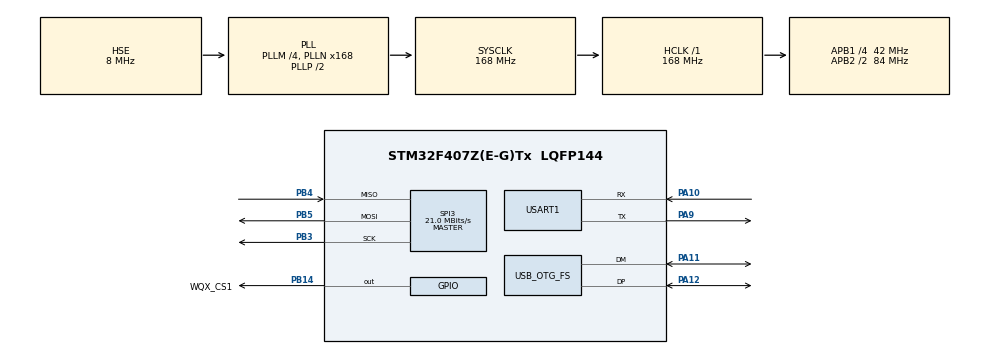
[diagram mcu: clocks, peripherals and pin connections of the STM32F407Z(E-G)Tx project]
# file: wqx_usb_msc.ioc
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Mcu.Family=STM32F4
Mcu.Name=STM32F407Z(E-G)Tx
Mcu.Package=LQFP144
NVIC.OTG_FS_IRQn=true\:0\:0\:false\:false\:true\:false\:true\:true
NVIC.PriorityGroup=NVIC_PRIORITYGROUP_4
PA10.Mode=Asynchronous
PA10.Signal=USART1_RX
PA11.Mode=Device_Only
PA11.Signal=USB_OTG_FS_DM
PA12.Mode=Device_Only
PA12.Signal=USB_OTG_FS_DP
PA13.Mode=Serial_Wire
PA13.Signal=SYS_JTMS-SWDIO
PA14.Mode=Serial_Wire
PA14.Signal=SYS_JTCK-SWCLK
PA9.Mode=Asynchronous
PA9.Signal=USART1_TX
PB14.GPIO_Label=WQX_CS1
PB14.GPIO_PuPd=GPIO_PULLUP
PB14.GPIO_Speed=GPIO_SPEED_FREQ_VERY_HIGH
PB14.PinState=GPIO_PIN_RESET
PB14.Signal=GPIO_Output
PB3.Mode=Full_Duplex_Master
PB3.Signal=SPI3_SCK
PB4.Mode=Full_Duplex_Master
PB4.Signal=SPI3_MISO
PB5.Mode=Full_Duplex_Master
PB5.Signal=SPI3_MOSI
PH0-OSC_IN.Mode=HSE-External-Oscillator
PH0-OSC_IN.Signal=RCC_OSC_IN
PH1-OSC_OUT.Mode=HSE-External-Oscillator
PH1-OSC_OUT.Signal=RCC_OSC_OUT
ProjectManager.HeapSize=0x10
ProjectManager.StackSize=0x1000
ProjectManager.TargetToolchain=STM32CubeIDE
RCC.48MHZClocksFreq_Value=48000000
RCC.AHBFreq_Value=168000000
RCC.APB1CLKDivider=RCC_HCLK_DIV4
RCC.APB1Freq_Value=42000000
RCC.APB1TimFreq_Value=84000000
RCC.APB2CLKDivider=RCC_HCLK_DIV2
RCC.APB2Freq_Value=84000000
RCC.APB2TimFreq_Value=168000000
RCC.CortexFreq_Value=168000000
RCC.HCLKFreq_Value=168000000
RCC.HSE_VALUE=8000000
RCC.HSI_VALUE=16000000
RCC.LSE_VALUE=32768
RCC.PLLM=4
RCC.PLLN=168
RCC.PLLQ=7
RCC.PLLSourceVirtual=RCC_PLLSOURCE_HSE
RCC.SYSCLKFreq_VALUE=168000000
RCC.SYSCLKSource=RCC_SYSCLKSOURCE_PLLCLK
RCC.VCOOutputFreq_Value=336000000
SPI3.CalculateBaudRate=21.0 MBits/s
SPI3.Direction=SPI_DIRECTION_2LINES
SPI3.Mode=SPI_MODE_MASTER
SPI3.VirtualType=VM_MASTER
USART1.VirtualMode=VM_ASYNC
USB_DEVICE.CLASS_NAME_FS=MSC
USB_DEVICE.MSC_MEDIA_PACKET-MSC_FS=4096
USB_DEVICE.USBD_MAX_STR_DESC_SIZ-MSC_FS=4096
USB_DEVICE.USBD_SELF_POWERED-MSC_FS=0
USB_DEVICE.VirtualMode-MSC_FS=Msc
USB_DEVICE.VirtualModeFS=Msc_FS
USB_OTG_FS.VirtualMode=Device_Only
VP_USB_DEVICE_VS_USB_DEVICE_MSC_FS.Mode=MSC_FS
board=custom

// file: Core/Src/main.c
/* USER CODE BEGIN Header */
/**
  ******************************************************************************
  * @file           : main.c
  * @brief          : Main program body
  ******************************************************************************
  * @attention
  *
  * Copyright (c) 2024 STMicroelectronics.
  * All rights reserved.
  *
  * This software is licensed under terms that can be found in the LICENSE file
  * in the root directory of this software component.
  * If no LICENSE file comes with this software, it is provided AS-IS.
  *
  ******************************************************************************
  */
/* USER CODE END Header */
#include "main.h"
#include "spi.h"
#include "usart.h"
#include "usb_device.h"
#include "gpio.h"

/* USER CODE BEGIN Includes */
#include "stdio.h"
#include "sys.h"
#include "w25qxx.h"
/* USER CODE END Includes */

void SystemClock_Config(void);

int main(void)
{

  /* MCU Configuration--------------------------------------------------------*/

  /* Reset of all peripherals, Initializes the Flash interface and the Systick. */
  HAL_Init();

  /* Configure the system clock */
  SystemClock_Config();

  /* Initialize all configured peripherals */
  MX_GPIO_Init();
  MX_SPI3_Init();
  MX_USART1_UART_Init();
  MX_USB_DEVICE_Init();
  /* USER CODE BEGIN 2 */
  //WQX_Init();
  //WQX_test();
  /* USER CODE END 2 */

  /* Infinite loop */
  while (1)
  {

    /* USER CODE BEGIN 3 */
    printf("wqx msc\r\n");
    delay_ms(500);
  }
  /* USER CODE END 3 */
}

void SystemClock_Config(void)
{
  RCC_OscInitTypeDef RCC_OscInitStruct = {0};
  RCC_ClkInitTypeDef RCC_ClkInitStruct = {0};

  /** Configure the main internal regulator output voltage
  */
  __HAL_RCC_PWR_CLK_ENABLE();
  __HAL_PWR_VOLTAGESCALING_CONFIG(PWR_REGULATOR_VOLTAGE_SCALE1);

  /** Initializes the RCC Oscillators according to the specified parameters
  * in the RCC_OscInitTypeDef structure.
  */
  RCC_OscInitStruct.OscillatorType = RCC_OSCILLATORTYPE_HSE;
  RCC_OscInitStruct.HSEState = RCC_HSE_ON;
  RCC_OscInitStruct.PLL.PLLState = RCC_PLL_ON;
  RCC_OscInitStruct.PLL.PLLSource = RCC_PLLSOURCE_HSE;
  RCC_OscInitStruct.PLL.PLLM = 4;
  RCC_OscInitStruct.PLL.PLLN = 168;
  RCC_OscInitStruct.PLL.PLLP = RCC_PLLP_DIV2;
  RCC_OscInitStruct.PLL.PLLQ = 7;
  if (HAL_RCC_OscConfig(&RCC_OscInitStruct) != HAL_OK)
  {
    Error_Handler();
  }

  /** Initializes the CPU, AHB and APB buses clocks
  */
  RCC_ClkInitStruct.ClockType = RCC_CLOCKTYPE_HCLK|RCC_CLOCKTYPE_SYSCLK
                              |RCC_CLOCKTYPE_PCLK1|RCC_CLOCKTYPE_PCLK2;
  RCC_ClkInitStruct.SYSCLKSource = RCC_SYSCLKSOURCE_PLLCLK;
  RCC_ClkInitStruct.AHBCLKDivider = RCC_SYSCLK_DIV1;
  RCC_ClkInitStruct.APB1CLKDivider = RCC_HCLK_DIV4;
  RCC_ClkInitStruct.APB2CLKDivider = RCC_HCLK_DIV2;

  if (HAL_RCC_ClockConfig(&RCC_ClkInitStruct, FLASH_LATENCY_5) != HAL_OK)
  {
    Error_Handler();
  }
}

void Error_Handler(void)
{
  __disable_irq();
  while (1)
  {
  }
}
